AUTOSAR XML (schema 00044)
package /E40_Platform_System_SystemPackage/Components
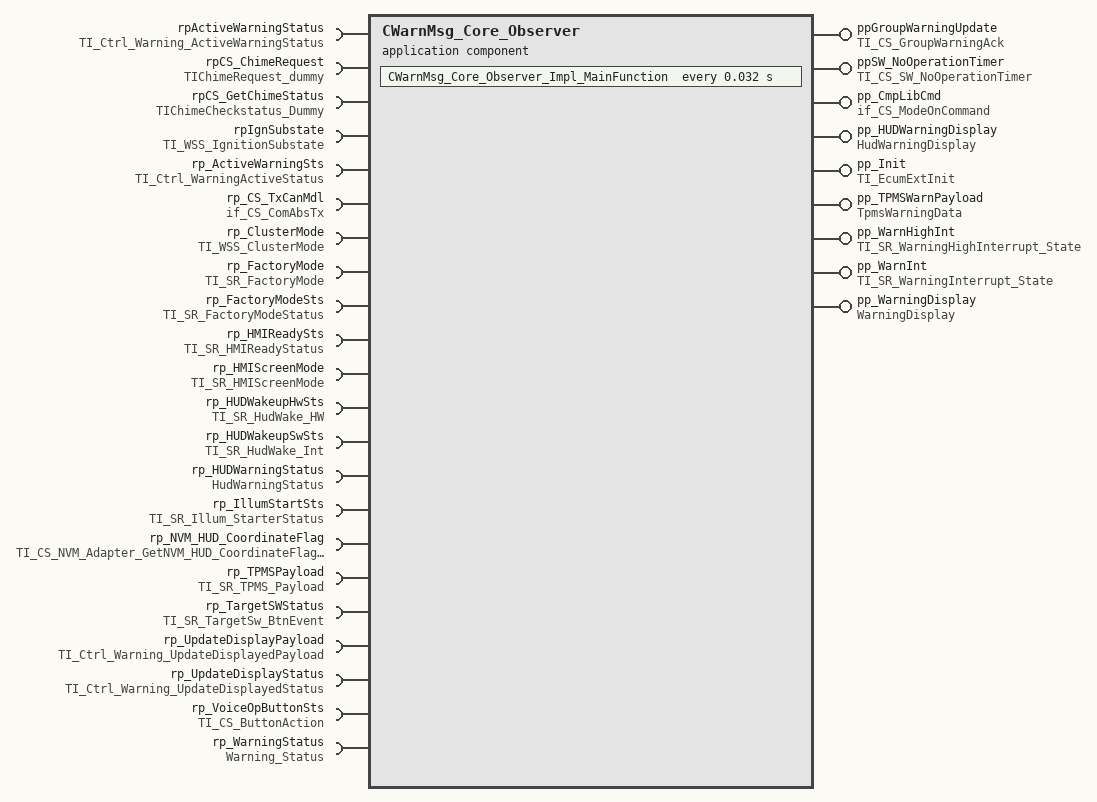
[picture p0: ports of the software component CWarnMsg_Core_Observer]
  application sw component type CWarnMsg_Core_Observer
    9 x provide port:
      ppGroupWarningUpdate: server-com-spec{operation=GroupWrnAck, queue-length=1}, provided-interface=TI_CS_GroupWarningAck
      ppSW_NoOperationTimer: server-com-spec{operation=SW_NoOperationTimer, queue-length=1}, provided-interface=TI_CS_SW_NoOperationTimer
      pp_CmpLibCmd: server-com-spec{operation=Impl_OnCommand, queue-length=1}, provided-interface=if_CS_ModeOnCommand
      pp_HUDWarningDisplay: nonqueued-sender-com-spec{data-element=HudWarningDisplayData, init-value=constant-reference=CWarnMsg_Core_ObserverHudWarningDisplayDataValue0}, provided-interface=HudWarningDisplay
      pp_Init: server-com-spec{operation=Init, queue-length=1}, provided-interface=TI_EcumExtInit
      pp_TPMSWarnPayload: nonqueued-sender-com-spec{data-element=TpmsWarningDataData, init-value=constant-reference=CWarnMsg_Core_ObserverTpmsWarningDataDataValue0}, provided-interface=TpmsWarningData
      pp_WarnHighInt: nonqueued-sender-com-spec{data-element=WarningHighInterrupt_State, init-value=constant-reference=CWarnMsg_Core_ObserverWarningHighInterrupt_StateValue0}, provided-interface=TI_SR_WarningHighInterrupt_State
      pp_WarnInt: nonqueued-sender-com-spec{data-element=WarningInterrupt_State, init-value=constant-reference=CWarnMsg_Core_ObserverWarningInterrupt_StateValue0}, provided-interface=TI_SR_WarningInterrupt_State
      pp_WarningDisplay: nonqueued-sender-com-spec{data-element=WarningDisplayData, init-value=constant-reference=CWarnMsg_Core_ObserverWarningDisplayDataValue0}, provided-interface=WarningDisplay
    22 x require port:
      rpActiveWarningStatus: client-com-spec=GetActiveWarningStatus, required-interface=TI_Ctrl_Warning_ActiveWarningStatus
      rpCS_ChimeRequest: nonqueued-receiver-com-spec{data-element=Chime_Request, init-value=constant-reference=CWarnMsg_Core_ObserverChime_RequestValue0}, required-interface=TIChimeRequest_dummy
      rpCS_GetChimeStatus: nonqueued-receiver-com-spec{data-element=Chime_Status, init-value=constant-reference=CWarnMsg_Core_ObserverChime_StatusValue0}, required-interface=TIChimeCheckstatus_Dummy
      rpIgnSubstate: nonqueued-receiver-com-spec{data-element=IgnitionSubstate, init-value=constant-reference=CWarnMsg_Core_ObserverIgnitionSubstateValue0}, required-interface=TI_WSS_IgnitionSubstate
      rp_ActiveWarningSts: client-com-spec=GetWarningActiveStatus, required-interface=TI_Ctrl_WarningActiveStatus
      rp_CS_TxCanMdl: required-interface=if_CS_ComAbsTx
        required-com-specs:
          TxCan_ClearCanSignalTxConfirmation
          TxCan_GetCanSignalTxConfirmation
          TxCan_SetSignalFromRetentionBuffer
          TxCan_SetSignalValue
          TxCan_SetSignalValueU8Arr
      rp_ClusterMode: nonqueued-receiver-com-spec{data-element=WSSCurrentClusterMode, init-value=constant-reference=CWarnMsg_Core_ObserverWSSCurrentClusterModeValue0}, required-interface=TI_WSS_ClusterMode
      rp_FactoryMode: nonqueued-receiver-com-spec{data-element=FactoryMode, init-value=constant-reference=CWarnMsg_Core_ObserverFactoryModeValue0}, required-interface=TI_SR_FactoryMode
      rp_FactoryModeSts: nonqueued-receiver-com-spec{data-element=FactoryModeStatus, init-value=constant-reference=CWarnMsg_Core_ObserverFactoryModeStatusValue0}, required-interface=TI_SR_FactoryModeStatus
      rp_HMIReadySts: nonqueued-receiver-com-spec{data-element=HMI_ReadyStatus, init-value=constant-reference=CWarnMsg_Core_ObserverHMI_ReadyStatusValue0}, required-interface=TI_SR_HMIReadyStatus
      rp_HMIScreenMode: nonqueued-receiver-com-spec{data-element=HMIScreenMode_Status, init-value=constant-reference=CWarnMsg_Core_ObserverHMIScreenMode_StatusValue0}, required-interface=TI_SR_HMIScreenMode
      rp_HUDWakeupHwSts: nonqueued-receiver-com-spec{data-element=WakeType_Hw, init-value=constant-reference=CWarnMsg_Core_ObserverWakeType_HwValue0}, required-interface=TI_SR_HudWake_HW
      rp_HUDWakeupSwSts: nonqueued-receiver-com-spec{data-element=WakeType_Int, init-value=constant-reference=CWarnMsg_Core_ObserverWakeType_IntValue0}, required-interface=TI_SR_HudWake_Int
      rp_HUDWarningStatus: nonqueued-receiver-com-spec{data-element=HudWarningStatusData, init-value=constant-reference=CWarnMsg_Core_ObserverHudWarningStatusDataValue0}, required-interface=HudWarningStatus
      rp_IllumStartSts: nonqueued-receiver-com-spec{data-element=StarterStatus_Out, init-value=constant-reference=CWarnMsg_Core_ObserverStarterStatus_OutValue0}, required-interface=TI_SR_Illum_StarterStatus
      rp_NVM_HUD_CoordinateFlag: nonqueued-receiver-com-spec{data-element=NvmData, init-value=constant-reference=CWarnMsg_Core_ObserverNvmDataValue0}, required-interface=TI_CS_NVM_Adapter_GetNVM_HUD_CoordinateFlag_Dummy
      rp_TPMSPayload: nonqueued-receiver-com-spec{data-element=Tpms_Payload, init-value=constant-reference=CWarnMsg_Core_ObserverTpms_PayloadValue0}, required-interface=TI_SR_TPMS_Payload
      rp_TargetSWStatus: nonqueued-receiver-com-spec{data-element=TargetSw, init-value=constant-reference=CWarnMsg_Core_ObserverTargetSwValue0}, required-interface=TI_SR_TargetSw_BtnEvent
      rp_UpdateDisplayPayload: client-com-spec=SetWarningDisplayedPayload, required-interface=TI_Ctrl_Warning_UpdateDisplayedPayload
      rp_UpdateDisplayStatus: client-com-spec=SetWarningDisplayedStatus, required-interface=TI_Ctrl_Warning_UpdateDisplayedStatus
      rp_VoiceOpButtonSts: client-com-spec=GetButtonStatus, required-interface=TI_CS_ButtonAction
      rp_WarningStatus: nonqueued-receiver-com-spec{data-element=WarningStatusData, init-value=constant-reference=CWarnMsg_Core_ObserverWarningStatusDataValue0}, required-interface=Warning_Status
    behavior IB_CWarnMsg_Core_Observer
      operation invoked event OIE_ppGroupWarningUpdate_CWarnMsg_Core_Observer_GroupWrnAckTrigByGroupWrnAck: start-on-event=CWarnMsg_Core_Observer_GroupWrnAck, operation=ppGroupWarningUpdate.GroupWrnAck
      timing event TECWarnMsg_Core_Observer_Impl_MainFunction: start-on-event=CWarnMsg_Core_Observer_Impl_MainFunction, period=0.032
      operation invoked event OIE_pp_CmpLibCmd_CWarnMsg_Core_Observer_Impl_OnCommandTrigByImpl_OnCommand: start-on-event=CWarnMsg_Core_Observer_Impl_OnCommand, operation=pp_CmpLibCmd.Impl_OnCommand
      operation invoked event OIE_pp_Init_CWarnMsg_Core_Observer_InitTrigByInit: start-on-event=CWarnMsg_Core_Observer_Init, operation=pp_Init.Init
      data received event DREOnDre_UCL_HudWarnStatusTrigByHudWarningStatusData: start-on-event=OnDre_UCL_HudWarnStatus, data=rp_HUDWarningStatus.HudWarningStatusData
      data received event DREOnDre_UCL_WarnStatusTrigByWarningStatusData: start-on-event=OnDre_UCL_WarnStatus, data=rp_WarningStatus.WarningStatusData
      operation invoked event OIE_ppSW_NoOperationTimer_CWarnMsg_Core_Observer_SW_NoOperationTimerTrigBySW_NoOperationTimer: start-on-event=CWarnMsg_Core_Observer_SW_NoOperationTimer, operation=ppSW_NoOperationTimer.SW_NoOperationTimer
      port-api-options:
        enable-take-address=false, indirect-api=false, port=ppGroupWarningUpdate
        enable-take-address=false, indirect-api=false, port=ppSW_NoOperationTimer
        enable-take-address=false, indirect-api=false, port=pp_CmpLibCmd
        enable-take-address=false, indirect-api=false, port=pp_HUDWarningDisplay
        enable-take-address=false, indirect-api=false, port=pp_Init
        enable-take-address=false, indirect-api=false, port=pp_TPMSWarnPayload
        enable-take-address=false, indirect-api=false, port=pp_WarnHighInt
        enable-take-address=false, indirect-api=false, port=pp_WarnInt
        enable-take-address=false, indirect-api=false, port=pp_WarningDisplay
        enable-take-address=false, indirect-api=false, port=rpActiveWarningStatus
        enable-take-address=false, indirect-api=false, port=rpCS_ChimeRequest
        enable-take-address=false, indirect-api=false, port=rpCS_GetChimeStatus
        enable-take-address=false, indirect-api=false, port=rpIgnSubstate
        enable-take-address=false, indirect-api=false, port=rp_ActiveWarningSts
        enable-take-address=false, indirect-api=false, port=rp_CS_TxCanMdl
        enable-take-address=false, indirect-api=false, port=rp_ClusterMode
        enable-take-address=false, indirect-api=false, port=rp_FactoryMode
        enable-take-address=false, indirect-api=false, port=rp_FactoryModeSts
        enable-take-address=false, indirect-api=false, port=rp_HMIReadySts
        enable-take-address=false, indirect-api=false, port=rp_HMIScreenMode
        enable-take-address=false, indirect-api=false, port=rp_HUDWakeupHwSts
        enable-take-address=false, indirect-api=false, port=rp_HUDWakeupSwSts
        enable-take-address=false, indirect-api=false, port=rp_HUDWarningStatus
        enable-take-address=false, indirect-api=false, port=rp_IllumStartSts
        enable-take-address=false, indirect-api=false, port=rp_NVM_HUD_CoordinateFlag
        enable-take-address=false, indirect-api=false, port=rp_TPMSPayload
        enable-take-address=false, indirect-api=false, port=rp_TargetSWStatus
        enable-take-address=false, indirect-api=false, port=rp_UpdateDisplayPayload
        enable-take-address=false, indirect-api=false, port=rp_UpdateDisplayStatus
        enable-take-address=false, indirect-api=false, port=rp_VoiceOpButtonSts
        enable-take-address=false, indirect-api=false, port=rp_WarningStatus
      7 x runnable, all with can-be-invoked-concurrently=true:
        CWarnMsg_Core_Observer_GroupWrnAck
        CWarnMsg_Core_Observer_Impl_MainFunction
          data-receive-point-by-arguments:
            16 x access:
              DRA_rpCS_ChimeRequest_Chime_Request: accessed-variable=rpCS_ChimeRequest.Chime_Request
              DRA_rpCS_GetChimeStatus_Chime_Status: accessed-variable=rpCS_GetChimeStatus.Chime_Status
              DRA_rpIgnSubstate_IgnitionSubstate: accessed-variable=rpIgnSubstate.IgnitionSubstate
              DRA_rp_ClusterMode_WSSCurrentClusterMode: accessed-variable=rp_ClusterMode.WSSCurrentClusterMode
              DRA_rp_FactoryMode_FactoryMode: accessed-variable=rp_FactoryMode.FactoryMode
              DRA_rp_FactoryModeSts_FactoryModeStatus: accessed-variable=rp_FactoryModeSts.FactoryModeStatus
              DRA_rp_HMIReadySts_HMI_ReadyStatus: accessed-variable=rp_HMIReadySts.HMI_ReadyStatus
              DRA_rp_HMIScreenMode_HMIScreenMode_Status: accessed-variable=rp_HMIScreenMode.HMIScreenMode_Status
              DRA_rp_HUDWakeupHwSts_WakeType_Hw: accessed-variable=rp_HUDWakeupHwSts.WakeType_Hw
              DRA_rp_HUDWakeupSwSts_WakeType_Int: accessed-variable=rp_HUDWakeupSwSts.WakeType_Int
              DRA_rp_HUDWarningStatus_HudWarningStatusData: accessed-variable=rp_HUDWarningStatus.HudWarningStatusData
              DRA_rp_IllumStartSts_StarterStatus_Out: accessed-variable=rp_IllumStartSts.StarterStatus_Out
              DRA_rp_NVM_HUD_CoordinateFlag_NvmData: accessed-variable=rp_NVM_HUD_CoordinateFlag.NvmData
              DRA_rp_TPMSPayload_Tpms_Payload: accessed-variable=rp_TPMSPayload.Tpms_Payload
              DRA_rp_TargetSWStatus_TargetSw: accessed-variable=rp_TargetSWStatus.TargetSw
              DRA_rp_WarningStatus_WarningStatusData: accessed-variable=rp_WarningStatus.WarningStatusData
          data-send-points:
            5 x access:
              DWA_pp_HUDWarningDisplay_HudWarningDisplayData: accessed-variable=pp_HUDWarningDisplay.HudWarningDisplayData
              DWA_pp_TPMSWarnPayload_TpmsWarningDataData: accessed-variable=pp_TPMSWarnPayload.TpmsWarningDataData
              DWA_pp_WarnHighInt_WarningHighInterrupt_State: accessed-variable=pp_WarnHighInt.WarningHighInterrupt_State
              DWA_pp_WarnInt_WarningInterrupt_State: accessed-variable=pp_WarnInt.WarningInterrupt_State
              DWA_pp_WarningDisplay_WarningDisplayData: accessed-variable=pp_WarningDisplay.WarningDisplayData
          10 x sync call:
            OA_rpActiveWarningStatus_GetActiveWarningStatus: operation=rpActiveWarningStatus.GetActiveWarningStatus
            OA_rp_ActiveWarningSts_GetWarningActiveStatus: operation=rp_ActiveWarningSts.GetWarningActiveStatus
            OA_rp_CS_TxCanMdl_TxCan_ClearCanSignalTxConfirmation: operation=rp_CS_TxCanMdl.TxCan_ClearCanSignalTxConfirmation
            OA_rp_CS_TxCanMdl_TxCan_GetCanSignalTxConfirmation: operation=rp_CS_TxCanMdl.TxCan_GetCanSignalTxConfirmation
            OA_rp_CS_TxCanMdl_TxCan_SetSignalFromRetentionBuffer: operation=rp_CS_TxCanMdl.TxCan_SetSignalFromRetentionBuffer
            OA_rp_CS_TxCanMdl_TxCan_SetSignalValue: operation=rp_CS_TxCanMdl.TxCan_SetSignalValue
            OA_rp_CS_TxCanMdl_TxCan_SetSignalValueU8Arr: operation=rp_CS_TxCanMdl.TxCan_SetSignalValueU8Arr
            OA_rp_UpdateDisplayPayload_SetWarningDisplayedPayload: operation=rp_UpdateDisplayPayload.SetWarningDisplayedPayload
            OA_rp_UpdateDisplayStatus_SetWarningDisplayedStatus: operation=rp_UpdateDisplayStatus.SetWarningDisplayedStatus
            OA_rp_VoiceOpButtonSts_GetButtonStatus: operation=rp_VoiceOpButtonSts.GetButtonStatus
        CWarnMsg_Core_Observer_Impl_OnCommand
        CWarnMsg_Core_Observer_Init
        OnDre_UCL_HudWarnStatus
          data-receive-point-by-arguments:
            16 x access:
              DRA_rpCS_ChimeRequest_Chime_Request: accessed-variable=rpCS_ChimeRequest.Chime_Request
              DRA_rpCS_GetChimeStatus_Chime_Status: accessed-variable=rpCS_GetChimeStatus.Chime_Status
              DRA_rpIgnSubstate_IgnitionSubstate: accessed-variable=rpIgnSubstate.IgnitionSubstate
              DRA_rp_ClusterMode_WSSCurrentClusterMode: accessed-variable=rp_ClusterMode.WSSCurrentClusterMode
              DRA_rp_FactoryMode_FactoryMode: accessed-variable=rp_FactoryMode.FactoryMode
              DRA_rp_FactoryModeSts_FactoryModeStatus: accessed-variable=rp_FactoryModeSts.FactoryModeStatus
              DRA_rp_HMIReadySts_HMI_ReadyStatus: accessed-variable=rp_HMIReadySts.HMI_ReadyStatus
              DRA_rp_HMIScreenMode_HMIScreenMode_Status: accessed-variable=rp_HMIScreenMode.HMIScreenMode_Status
              DRA_rp_HUDWakeupHwSts_WakeType_Hw: accessed-variable=rp_HUDWakeupHwSts.WakeType_Hw
              DRA_rp_HUDWakeupSwSts_WakeType_Int: accessed-variable=rp_HUDWakeupSwSts.WakeType_Int
              DRA_rp_HUDWarningStatus_HudWarningStatusData: accessed-variable=rp_HUDWarningStatus.HudWarningStatusData
              DRA_rp_IllumStartSts_StarterStatus_Out: accessed-variable=rp_IllumStartSts.StarterStatus_Out
              DRA_rp_NVM_HUD_CoordinateFlag_NvmData: accessed-variable=rp_NVM_HUD_CoordinateFlag.NvmData
              DRA_rp_TPMSPayload_Tpms_Payload: accessed-variable=rp_TPMSPayload.Tpms_Payload
              DRA_rp_TargetSWStatus_TargetSw: accessed-variable=rp_TargetSWStatus.TargetSw
              DRA_rp_WarningStatus_WarningStatusData: accessed-variable=rp_WarningStatus.WarningStatusData
          data-send-points:
            5 x access:
              DWA_pp_HUDWarningDisplay_HudWarningDisplayData: accessed-variable=pp_HUDWarningDisplay.HudWarningDisplayData
              DWA_pp_TPMSWarnPayload_TpmsWarningDataData: accessed-variable=pp_TPMSWarnPayload.TpmsWarningDataData
              DWA_pp_WarnHighInt_WarningHighInterrupt_State: accessed-variable=pp_WarnHighInt.WarningHighInterrupt_State
              DWA_pp_WarnInt_WarningInterrupt_State: accessed-variable=pp_WarnInt.WarningInterrupt_State
              DWA_pp_WarningDisplay_WarningDisplayData: accessed-variable=pp_WarningDisplay.WarningDisplayData
          10 x sync call:
            OA_rpActiveWarningStatus_GetActiveWarningStatus: operation=rpActiveWarningStatus.GetActiveWarningStatus
            OA_rp_ActiveWarningSts_GetWarningActiveStatus: operation=rp_ActiveWarningSts.GetWarningActiveStatus
            OA_rp_CS_TxCanMdl_TxCan_ClearCanSignalTxConfirmation: operation=rp_CS_TxCanMdl.TxCan_ClearCanSignalTxConfirmation
            OA_rp_CS_TxCanMdl_TxCan_GetCanSignalTxConfirmation: operation=rp_CS_TxCanMdl.TxCan_GetCanSignalTxConfirmation
            OA_rp_CS_TxCanMdl_TxCan_SetSignalFromRetentionBuffer: operation=rp_CS_TxCanMdl.TxCan_SetSignalFromRetentionBuffer
            OA_rp_CS_TxCanMdl_TxCan_SetSignalValue: operation=rp_CS_TxCanMdl.TxCan_SetSignalValue
            OA_rp_CS_TxCanMdl_TxCan_SetSignalValueU8Arr: operation=rp_CS_TxCanMdl.TxCan_SetSignalValueU8Arr
            OA_rp_UpdateDisplayPayload_SetWarningDisplayedPayload: operation=rp_UpdateDisplayPayload.SetWarningDisplayedPayload
            OA_rp_UpdateDisplayStatus_SetWarningDisplayedStatus: operation=rp_UpdateDisplayStatus.SetWarningDisplayedStatus
            OA_rp_VoiceOpButtonSts_GetButtonStatus: operation=rp_VoiceOpButtonSts.GetButtonStatus
        OnDre_UCL_WarnStatus
          data-receive-point-by-arguments:
            16 x access:
              DRA_rpCS_ChimeRequest_Chime_Request: accessed-variable=rpCS_ChimeRequest.Chime_Request
              DRA_rpCS_GetChimeStatus_Chime_Status: accessed-variable=rpCS_GetChimeStatus.Chime_Status
              DRA_rpIgnSubstate_IgnitionSubstate: accessed-variable=rpIgnSubstate.IgnitionSubstate
              DRA_rp_ClusterMode_WSSCurrentClusterMode: accessed-variable=rp_ClusterMode.WSSCurrentClusterMode
              DRA_rp_FactoryMode_FactoryMode: accessed-variable=rp_FactoryMode.FactoryMode
              DRA_rp_FactoryModeSts_FactoryModeStatus: accessed-variable=rp_FactoryModeSts.FactoryModeStatus
              DRA_rp_HMIReadySts_HMI_ReadyStatus: accessed-variable=rp_HMIReadySts.HMI_ReadyStatus
              DRA_rp_HMIScreenMode_HMIScreenMode_Status: accessed-variable=rp_HMIScreenMode.HMIScreenMode_Status
              DRA_rp_HUDWakeupHwSts_WakeType_Hw: accessed-variable=rp_HUDWakeupHwSts.WakeType_Hw
              DRA_rp_HUDWakeupSwSts_WakeType_Int: accessed-variable=rp_HUDWakeupSwSts.WakeType_Int
              DRA_rp_HUDWarningStatus_HudWarningStatusData: accessed-variable=rp_HUDWarningStatus.HudWarningStatusData
              DRA_rp_IllumStartSts_StarterStatus_Out: accessed-variable=rp_IllumStartSts.StarterStatus_Out
              DRA_rp_NVM_HUD_CoordinateFlag_NvmData: accessed-variable=rp_NVM_HUD_CoordinateFlag.NvmData
              DRA_rp_TPMSPayload_Tpms_Payload: accessed-variable=rp_TPMSPayload.Tpms_Payload
              DRA_rp_TargetSWStatus_TargetSw: accessed-variable=rp_TargetSWStatus.TargetSw
              DRA_rp_WarningStatus_WarningStatusData: accessed-variable=rp_WarningStatus.WarningStatusData
          data-send-points:
            5 x access:
              DWA_pp_HUDWarningDisplay_HudWarningDisplayData: accessed-variable=pp_HUDWarningDisplay.HudWarningDisplayData
              DWA_pp_TPMSWarnPayload_TpmsWarningDataData: accessed-variable=pp_TPMSWarnPayload.TpmsWarningDataData
              DWA_pp_WarnHighInt_WarningHighInterrupt_State: accessed-variable=pp_WarnHighInt.WarningHighInterrupt_State
              DWA_pp_WarnInt_WarningInterrupt_State: accessed-variable=pp_WarnInt.WarningInterrupt_State
              DWA_pp_WarningDisplay_WarningDisplayData: accessed-variable=pp_WarningDisplay.WarningDisplayData
          10 x sync call:
            OA_rpActiveWarningStatus_GetActiveWarningStatus: operation=rpActiveWarningStatus.GetActiveWarningStatus
            OA_rp_ActiveWarningSts_GetWarningActiveStatus: operation=rp_ActiveWarningSts.GetWarningActiveStatus
            OA_rp_CS_TxCanMdl_TxCan_ClearCanSignalTxConfirmation: operation=rp_CS_TxCanMdl.TxCan_ClearCanSignalTxConfirmation
            OA_rp_CS_TxCanMdl_TxCan_GetCanSignalTxConfirmation: operation=rp_CS_TxCanMdl.TxCan_GetCanSignalTxConfirmation
            OA_rp_CS_TxCanMdl_TxCan_SetSignalFromRetentionBuffer: operation=rp_CS_TxCanMdl.TxCan_SetSignalFromRetentionBuffer
            OA_rp_CS_TxCanMdl_TxCan_SetSignalValue: operation=rp_CS_TxCanMdl.TxCan_SetSignalValue
            OA_rp_CS_TxCanMdl_TxCan_SetSignalValueU8Arr: operation=rp_CS_TxCanMdl.TxCan_SetSignalValueU8Arr
            OA_rp_UpdateDisplayPayload_SetWarningDisplayedPayload: operation=rp_UpdateDisplayPayload.SetWarningDisplayedPayload
            OA_rp_UpdateDisplayStatus_SetWarningDisplayedStatus: operation=rp_UpdateDisplayStatus.SetWarningDisplayedStatus
            OA_rp_VoiceOpButtonSts_GetButtonStatus: operation=rp_VoiceOpButtonSts.GetButtonStatus
        CWarnMsg_Core_Observer_SW_NoOperationTimer
          data-receive-point-by-arguments:
            16 x access:
              DRA_rpCS_ChimeRequest_Chime_Request: accessed-variable=rpCS_ChimeRequest.Chime_Request
              DRA_rpCS_GetChimeStatus_Chime_Status: accessed-variable=rpCS_GetChimeStatus.Chime_Status
              DRA_rpIgnSubstate_IgnitionSubstate: accessed-variable=rpIgnSubstate.IgnitionSubstate
              DRA_rp_ClusterMode_WSSCurrentClusterMode: accessed-variable=rp_ClusterMode.WSSCurrentClusterMode
              DRA_rp_FactoryMode_FactoryMode: accessed-variable=rp_FactoryMode.FactoryMode
              DRA_rp_FactoryModeSts_FactoryModeStatus: accessed-variable=rp_FactoryModeSts.FactoryModeStatus
              DRA_rp_HMIReadySts_HMI_ReadyStatus: accessed-variable=rp_HMIReadySts.HMI_ReadyStatus
              DRA_rp_HMIScreenMode_HMIScreenMode_Status: accessed-variable=rp_HMIScreenMode.HMIScreenMode_Status
              DRA_rp_HUDWakeupHwSts_WakeType_Hw: accessed-variable=rp_HUDWakeupHwSts.WakeType_Hw
              DRA_rp_HUDWakeupSwSts_WakeType_Int: accessed-variable=rp_HUDWakeupSwSts.WakeType_Int
              DRA_rp_HUDWarningStatus_HudWarningStatusData: accessed-variable=rp_HUDWarningStatus.HudWarningStatusData
              DRA_rp_IllumStartSts_StarterStatus_Out: accessed-variable=rp_IllumStartSts.StarterStatus_Out
              DRA_rp_NVM_HUD_CoordinateFlag_NvmData: accessed-variable=rp_NVM_HUD_CoordinateFlag.NvmData
              DRA_rp_TPMSPayload_Tpms_Payload: accessed-variable=rp_TPMSPayload.Tpms_Payload
              DRA_rp_TargetSWStatus_TargetSw: accessed-variable=rp_TargetSWStatus.TargetSw
              DRA_rp_WarningStatus_WarningStatusData: accessed-variable=rp_WarningStatus.WarningStatusData
          data-send-points:
            5 x access:
              DWA_pp_HUDWarningDisplay_HudWarningDisplayData: accessed-variable=pp_HUDWarningDisplay.HudWarningDisplayData
              DWA_pp_TPMSWarnPayload_TpmsWarningDataData: accessed-variable=pp_TPMSWarnPayload.TpmsWarningDataData
              DWA_pp_WarnHighInt_WarningHighInterrupt_State: accessed-variable=pp_WarnHighInt.WarningHighInterrupt_State
              DWA_pp_WarnInt_WarningInterrupt_State: accessed-variable=pp_WarnInt.WarningInterrupt_State
              DWA_pp_WarningDisplay_WarningDisplayData: accessed-variable=pp_WarningDisplay.WarningDisplayData
          10 x sync call:
            OA_rpActiveWarningStatus_GetActiveWarningStatus: operation=rpActiveWarningStatus.GetActiveWarningStatus
            OA_rp_ActiveWarningSts_GetWarningActiveStatus: operation=rp_ActiveWarningSts.GetWarningActiveStatus
            OA_rp_CS_TxCanMdl_TxCan_ClearCanSignalTxConfirmation: operation=rp_CS_TxCanMdl.TxCan_ClearCanSignalTxConfirmation
            OA_rp_CS_TxCanMdl_TxCan_GetCanSignalTxConfirmation: operation=rp_CS_TxCanMdl.TxCan_GetCanSignalTxConfirmation
            OA_rp_CS_TxCanMdl_TxCan_SetSignalFromRetentionBuffer: operation=rp_CS_TxCanMdl.TxCan_SetSignalFromRetentionBuffer
            OA_rp_CS_TxCanMdl_TxCan_SetSignalValue: operation=rp_CS_TxCanMdl.TxCan_SetSignalValue
            OA_rp_CS_TxCanMdl_TxCan_SetSignalValueU8Arr: operation=rp_CS_TxCanMdl.TxCan_SetSignalValueU8Arr
            OA_rp_UpdateDisplayPayload_SetWarningDisplayedPayload: operation=rp_UpdateDisplayPayload.SetWarningDisplayedPayload
            OA_rp_UpdateDisplayStatus_SetWarningDisplayedStatus: operation=rp_UpdateDisplayStatus.SetWarningDisplayedStatus
            OA_rp_VoiceOpButtonSts_GetButtonStatus: operation=rp_VoiceOpButtonSts.GetButtonStatus
  swc implementation IMPL_CWarnMsg_Core_Observer: behavior=IB_CWarnMsg_Core_Observer
